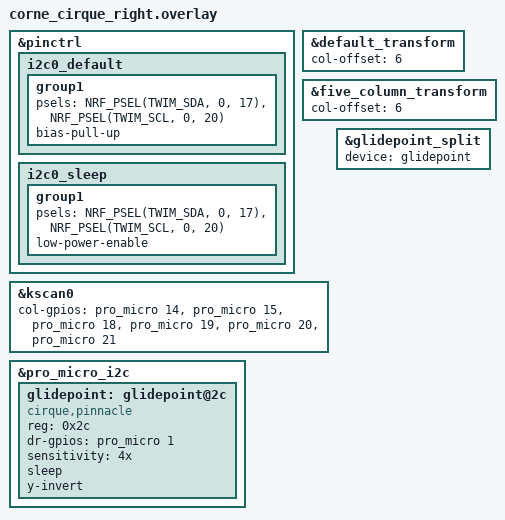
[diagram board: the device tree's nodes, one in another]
/*
 * Copyright (c) 2020 Pete Johanson
 *
 * SPDX-License-Identifier: MIT
 */

#include "corne_cirque.dtsi"

&pinctrl {
    i2c0_default: i2c0_default {
        group1 {
            psels = <NRF_PSEL(TWIM_SDA, 0, 17)>,
                <NRF_PSEL(TWIM_SCL, 0, 20)>;
            bias-pull-up;
        };
    };
    i2c0_sleep: i2c0_sleep {
        group1 {
            psels = <NRF_PSEL(TWIM_SDA, 0, 17)>,
                <NRF_PSEL(TWIM_SCL, 0, 20)>;
            low-power-enable;
        };
    };
};

&default_transform {
    col-offset = <6>;
};

&five_column_transform {
    col-offset = <6>;
};

&kscan0 {
    col-gpios
        = <&pro_micro 14 GPIO_ACTIVE_HIGH>
        , <&pro_micro 15 GPIO_ACTIVE_HIGH>
        , <&pro_micro 18 GPIO_ACTIVE_HIGH>
        , <&pro_micro 19 GPIO_ACTIVE_HIGH>
        , <&pro_micro 20 GPIO_ACTIVE_HIGH>
        , <&pro_micro 21 GPIO_ACTIVE_HIGH>
        ;
};

&pro_micro_i2c {
    status = "okay";

    glidepoint: glidepoint@2c {
        compatible = "cirque,pinnacle";
        reg = <0x2c>;
        status = "okay";
        dr-gpios = <&pro_micro 1 (GPIO_ACTIVE_HIGH)>;

        sensitivity = "4x";
        sleep;
        y-invert;
    };
};

&glidepoint_split {
    device = <&glidepoint>;
};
